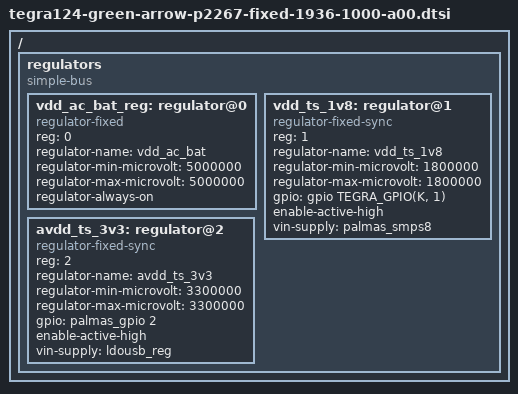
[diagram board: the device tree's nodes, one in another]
/*
 * tegra124-green-arrow-p2267-fixed-1936-1000-a00.dtsi: GPIO based regulators
 *
 * Copyright (c) 2015, NVIDIA CORPORATION.  All rights reserved.
 *
 * This program is free software; you can redistribute it and/or modify
 * it under the terms of the GNU General Public License as published by
 * the Free Software Foundation; either version 2 of the License, or
 * (at your option) any later version.
 *
 * This program is distributed in the hope that it will be useful, but WITHOUT
 * ANY WARRANTY; without even the implied warranty of MERCHANTABILITY or
 * FITNESS FOR A PARTICULAR PURPOSE.  See the GNU General Public License for
 * more details.
 */

#include <dt-bindings/gpio/tegra-gpio.h>

/ {
	regulators {
		compatible = "simple-bus";
		#address-cells = <1>;
		#size-cells = <0>;

		vdd_ac_bat_reg: regulator@0 {
			compatible = "regulator-fixed";
			reg = <0>;
			regulator-name = "vdd_ac_bat";
			regulator-min-microvolt = <5000000>;
			regulator-max-microvolt = <5000000>;
			regulator-always-on;
		};

		vdd_ts_1v8: regulator@1 {
			compatible = "regulator-fixed-sync";
			reg = <1>;
			regulator-name = "vdd_ts_1v8";
			regulator-min-microvolt = <1800000>;
			regulator-max-microvolt = <1800000>;
			gpio = <&gpio TEGRA_GPIO(K, 1) 0>;
			enable-active-high;
			vin-supply = <&palmas_smps8>;
		};

		avdd_ts_3v3: regulator@2 {
			compatible = "regulator-fixed-sync";
			reg = <2>;
			regulator-name = "avdd_ts_3v3";
			regulator-min-microvolt = <3300000>;
			regulator-max-microvolt = <3300000>;
			gpio = <&palmas_gpio 2 0>;
			enable-active-high;
			vin-supply = <&ldousb_reg>;
		};

	};
};
